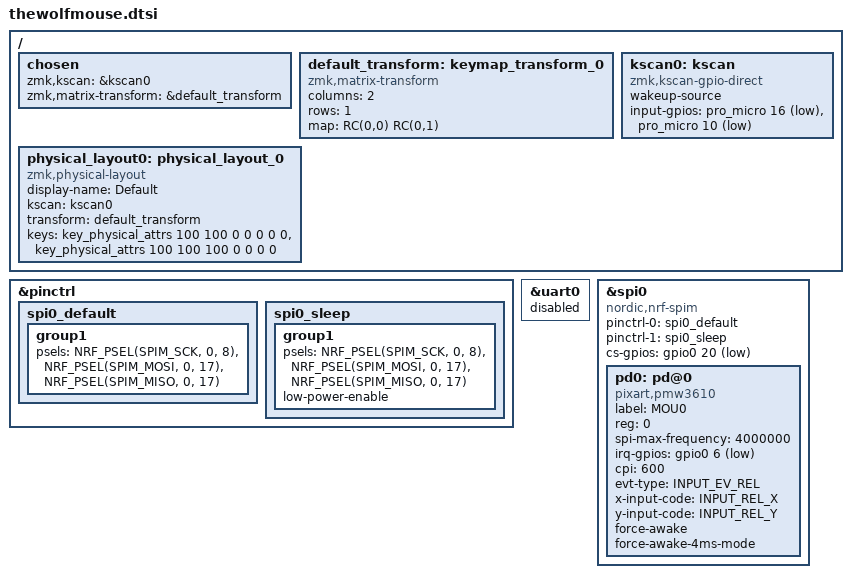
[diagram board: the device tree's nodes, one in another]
#include <physical_layouts.dtsi>
#include <dt-bindings/zmk/matrix_transform.h>

/ {
    chosen {
		zmk,kscan = &kscan0;
		zmk,matrix-transform = &default_transform;
	};

    default_transform: keymap_transform_0 {
        compatible = "zmk,matrix-transform";
        columns = <2>;
        rows = <1>;
        map = < RC(0,0) RC(0,1) >;
    };

    kscan0: kscan {
        compatible = "zmk,kscan-gpio-direct";
        wakeup-source;

        input-gpios
            = <&pro_micro 16 (GPIO_ACTIVE_LOW | GPIO_PULL_UP)>
            , <&pro_micro 10 (GPIO_ACTIVE_LOW | GPIO_PULL_UP)>
            ;
    };

    physical_layout0: physical_layout_0 {
        compatible = "zmk,physical-layout";
        display-name = "Default";

        kscan = <&kscan0>;
        transform = <&default_transform>;

        keys  //                     w   h    x    y     rot    rx    ry
            = <&key_physical_attrs 100 100    0    0       0     0     0>
            , <&key_physical_attrs 100 100  100    0       0     0     0>
            ;
    };
};

#include <zephyr/dt-bindings/input/input-event-codes.h>

&pinctrl {
    spi0_default: spi0_default {
        group1 {
            psels = <NRF_PSEL(SPIM_SCK, 0, 8)>,
                <NRF_PSEL(SPIM_MOSI, 0, 17)>,
                <NRF_PSEL(SPIM_MISO, 0, 17)>;
        };
    };

    spi0_sleep: spi0_sleep {
        group1 {
            psels = <NRF_PSEL(SPIM_SCK, 0, 8)>,
                <NRF_PSEL(SPIM_MOSI, 0, 17)>,
                <NRF_PSEL(SPIM_MISO, 0, 17)>;
            low-power-enable;
        };
    };
};

// release gpio1 11 & 12 from xiao_ble-pinctrl.dtsi
// for &trackball { irq-gpios } 可能不需要
&uart0 {
	status = "disabled";
};

&spi0 {
    status = "okay";
    compatible = "nordic,nrf-spim";
    pinctrl-0 = <&spi0_default>;
    pinctrl-1 = <&spi0_sleep>;
    pinctrl-names = "default", "sleep";
    cs-gpios = <&gpio0 20 GPIO_ACTIVE_LOW>;

    pd0: pd@0 {
        status = "okay";
        compatible = "pixart,pmw3610";
        label = "MOU0";
        reg = <0>;
        spi-max-frequency = <4000000>;
        irq-gpios = <&gpio0 6 (GPIO_ACTIVE_LOW | GPIO_PULL_UP)>;
        cpi = <600>;
		evt-type = <INPUT_EV_REL>;
		x-input-code = <INPUT_REL_X>;
		y-input-code = <INPUT_REL_Y>;
		force-awake;
		force-awake-4ms-mode;
    };
};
